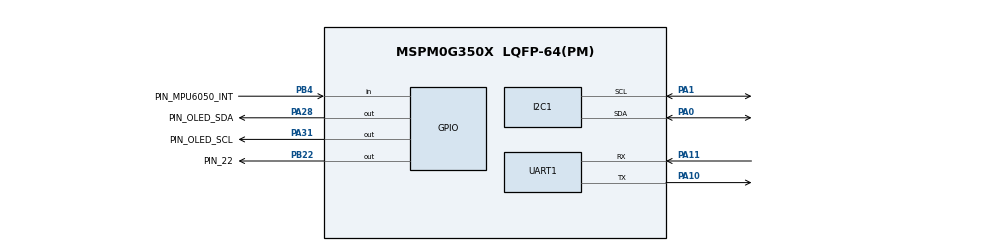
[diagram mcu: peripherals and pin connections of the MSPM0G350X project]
/**
 * @cliArgs --device "MSPM0G350X" --part "Default" --package "LQFP-64(PM)" --product "mspm0_sdk@2.10.00.04"
 * @versions {"tool":"1.26.2+4477"}
 */

/**
 * Import the modules used in this configuration.
 */
const GPIO   = scripting.addModule("/ti/driverlib/GPIO", {}, false);
const GPIO1  = GPIO.addInstance();
const GPIO2  = GPIO.addInstance();
const GPIO3  = GPIO.addInstance();
const I2C    = scripting.addModule("/ti/driverlib/I2C", {}, false);
const I2C1   = I2C.addInstance();
const SYSCTL = scripting.addModule("/ti/driverlib/SYSCTL");
const TIMER  = scripting.addModule("/ti/driverlib/TIMER", {}, false);
const TIMER1 = TIMER.addInstance();
const UART   = scripting.addModule("/ti/driverlib/UART", {}, false);
const UART1  = UART.addInstance();

/**
 * Write custom configuration values to the imported modules.
 */
const divider9       = system.clockTree["UDIV"];
divider9.divideValue = 2;

const gate7  = system.clockTree["MFCLKGATE"];
gate7.enable = true;

const multiplier2         = system.clockTree["PLL_QDIV"];
multiplier2.multiplyValue = 4;

const mux4       = system.clockTree["EXHFMUX"];
mux4.inputSelect = "EXHFMUX_XTAL";

const mux8       = system.clockTree["HSCLKMUX"];
mux8.inputSelect = "HSCLKMUX_SYSPLL0";

const mux12       = system.clockTree["SYSPLLMUX"];
mux12.inputSelect = "zSYSPLLMUX_HFCLK";

const pinFunction4        = system.clockTree["HFXT"];
pinFunction4.inputFreq    = 40;
pinFunction4.enable       = true;
pinFunction4.HFXTStartup  = 10;
pinFunction4.HFCLKMonitor = true;

GPIO1.$name                         = "LED";
GPIO1.port                          = "PORTB";
GPIO1.associatedPins[0].$name       = "PIN_22";
GPIO1.associatedPins[0].pin.$assign = "PB22";

const Board = scripting.addModule("/ti/driverlib/Board", {}, false);

GPIO2.$name                               = "GPIO_MPU6050_INT";
GPIO2.port                                = "PORTB";
GPIO2.associatedPins[0].$name             = "PIN_MPU6050_INT";
GPIO2.associatedPins[0].direction         = "INPUT";
GPIO2.associatedPins[0].internalResistor  = "PULL_UP";
GPIO2.associatedPins[0].interruptEn       = true;
GPIO2.associatedPins[0].interruptPriority = "3";
GPIO2.associatedPins[0].polarity          = "FALL";
GPIO2.associatedPins[0].pin.$assign       = "PB4";

GPIO3.$name                         = "GPIO_OLED_SW_I2C";
GPIO3.associatedPins.create(2);
GPIO3.associatedPins[0].$name       = "PIN_OLED_SDA";
GPIO3.associatedPins[0].pin.$assign = "PA28";
GPIO3.associatedPins[1].$name       = "PIN_OLED_SCL";
GPIO3.associatedPins[1].pin.$assign = "PA31";

I2C1.$name                     = "I2C_0";
I2C1.basicEnableController     = true;
I2C1.peripheral.$assign        = "I2C0";
I2C1.peripheral.sdaPin.$assign = "PA0";
I2C1.peripheral.sclPin.$assign = "PA1";
I2C1.sdaPinConfig.$name        = "ti_driverlib_gpio_GPIOPinGeneric2";
I2C1.sclPinConfig.$name        = "ti_driverlib_gpio_GPIOPinGeneric3";

SYSCTL.forceDefaultClkConfig = true;
SYSCTL.clockTreeEn           = true;

TIMER1.$name              = "TIMER_0";
TIMER1.timerPeriod        = "1 ms";
TIMER1.timerMode          = "PERIODIC";
TIMER1.interrupts         = ["ZERO"];
TIMER1.peripheral.$assign = "TIMG12";

UART1.$name                    = "UART_0";
UART1.enabledInterrupts        = ["RX"];
UART1.targetBaudRate           = 115200;
UART1.peripheral.rxPin.$assign = "PA11";
UART1.peripheral.txPin.$assign = "PA10";
UART1.txPinConfig.$name        = "ti_driverlib_gpio_GPIOPinGeneric0";
UART1.rxPinConfig.$name        = "ti_driverlib_gpio_GPIOPinGeneric1";

/**
 * Pinmux solution for unlocked pins/peripherals. This ensures that minor changes to the automatic solver in a future
 * version of the tool will not impact the pinmux you originally saw.  These lines can be completely deleted in order to
 * re-solve from scratch.
 */
pinFunction4.peripheral.$suggestSolution           = "SYSCTL";
pinFunction4.peripheral.hfxInPin.$suggestSolution  = "PA5";
pinFunction4.peripheral.hfxOutPin.$suggestSolution = "PA6";
Board.peripheral.$suggestSolution                  = "DEBUGSS";
Board.peripheral.swclkPin.$suggestSolution         = "PA20";
Board.peripheral.swdioPin.$suggestSolution         = "PA19";
UART1.peripheral.$suggestSolution                  = "UART0";
